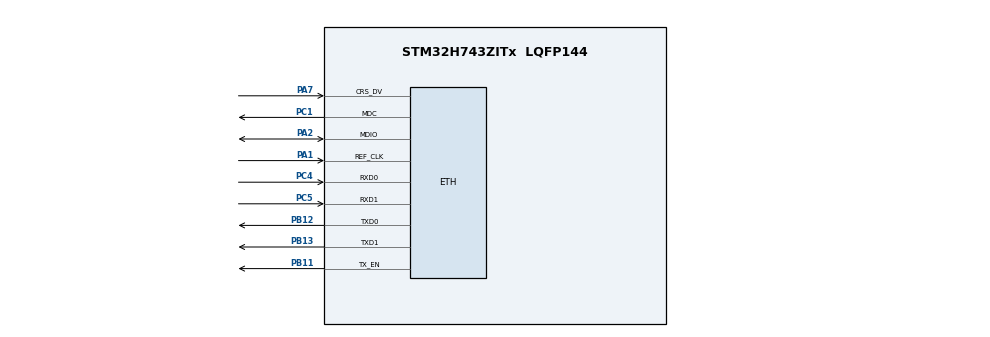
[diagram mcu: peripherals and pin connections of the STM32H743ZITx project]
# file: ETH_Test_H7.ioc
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CORTEX_M7.AccessPermission-Cortex_Memory_Protection_Unit_Region0_Settings=MPU_REGION_FULL_ACCESS
CORTEX_M7.AccessPermission-Cortex_Memory_Protection_Unit_Region1_Settings=MPU_REGION_FULL_ACCESS
CORTEX_M7.BaseAddress-Cortex_Memory_Protection_Unit_Region0_Settings=( uint32_t )&__ETH_BUFFERS_START
CORTEX_M7.BaseAddress-Cortex_Memory_Protection_Unit_Region1_Settings=( uint32_t )&__ETH_DESCRIPTORS_START
CORTEX_M7.CPU_DCache=Enabled
CORTEX_M7.CPU_ICache=Enabled
CORTEX_M7.DisableExec-Cortex_Memory_Protection_Unit_Region0_Settings=MPU_INSTRUCTION_ACCESS_DISABLE
CORTEX_M7.DisableExec-Cortex_Memory_Protection_Unit_Region1_Settings=MPU_INSTRUCTION_ACCESS_DISABLE
CORTEX_M7.Enable-Cortex_Memory_Protection_Unit_Region0_Settings=MPU_REGION_ENABLE
CORTEX_M7.Enable-Cortex_Memory_Protection_Unit_Region1_Settings=MPU_REGION_ENABLE
CORTEX_M7.IsBufferable-Cortex_Memory_Protection_Unit_Region1_Settings=MPU_ACCESS_BUFFERABLE
CORTEX_M7.MPU_Control=MPU_PRIVILEGED_DEFAULT
CORTEX_M7.Size-Cortex_Memory_Protection_Unit_Region0_Settings=MPU_REGION_SIZE_128KB
CORTEX_M7.Size-Cortex_Memory_Protection_Unit_Region1_Settings=MPU_REGION_SIZE_1KB
CORTEX_M7.TypeExtField-Cortex_Memory_Protection_Unit_Region0_Settings=MPU_TEX_LEVEL1
ETH.MediaInterface=HAL_ETH_RMII_MODE
Mcu.Family=STM32H7
Mcu.Name=STM32H743ZITx
Mcu.Package=LQFP144
NVIC.ETH_IRQn=true\:5\:0\:true\:false\:false\:true\:true\:true
NVIC.PriorityGroup=NVIC_PRIORITYGROUP_4
NVIC.TIM6_DAC_IRQn=true\:15\:0\:false\:false\:true\:false\:true\:true
NVIC.TimeBase=TIM6_DAC_IRQn
NVIC.TimeBaseIP=TIM6
PA1.Mode=RMII
PA1.Signal=ETH_REF_CLK
PA2.GPIO_Speed=GPIO_SPEED_FREQ_HIGH
PA2.Mode=RMII
PA2.Signal=ETH_MDIO
PA7.Mode=RMII
PA7.Signal=ETH_CRS_DV
PB11.GPIO_Speed=GPIO_SPEED_FREQ_VERY_HIGH
PB11.Mode=RMII
PB11.Signal=ETH_TX_EN
PB12.GPIO_Speed=GPIO_SPEED_FREQ_VERY_HIGH
PB12.Mode=RMII
PB12.Signal=ETH_TXD0
PB13.GPIO_Speed=GPIO_SPEED_FREQ_VERY_HIGH
PB13.Mode=RMII
PB13.Signal=ETH_TXD1
PC1.GPIO_Speed=GPIO_SPEED_FREQ_HIGH
PC1.Mode=RMII
PC1.Signal=ETH_MDC
PC4.GPIO_Speed=GPIO_SPEED_FREQ_VERY_HIGH
PC4.Mode=RMII
PC4.Signal=ETH_RXD0
PC5.GPIO_Speed=GPIO_SPEED_FREQ_VERY_HIGH
PC5.Mode=RMII
PC5.Signal=ETH_RXD1
PH0-OSC_IN\ (PH0).Mode=HSE-External-Clock-Source
PH0-OSC_IN\ (PH0).Signal=RCC_OSC_IN
ProjectManager.HeapSize=0x400
ProjectManager.StackSize=0x800
ProjectManager.TargetToolchain=STM32CubeIDE
RCC.ADCFreq_Value=16125000
RCC.APB1Freq_Value=120000000
RCC.APB2Freq_Value=120000000
RCC.APB3Freq_Value=120000000
RCC.APB4Freq_Value=120000000
RCC.CortexFreq_Value=480000000
RCC.D1PPRE=RCC_APB3_DIV2
RCC.D2PPRE1=RCC_APB1_DIV2
RCC.D2PPRE2=RCC_APB2_DIV2
RCC.D3PPRE=RCC_APB4_DIV2
RCC.DIVM1=1
RCC.DIVN1=120
RCC.HCLKFreq_Value=240000000
RCC.HPRE=RCC_HCLK_DIV2
RCC.HSE_VALUE=8000000
RCC.PLLFRACN=0
RCC.PLLSourceVirtual=RCC_PLLSOURCE_HSE
RCC.SYSCLKFreq_VALUE=480000000
RCC.SYSCLKSource=RCC_SYSCLKSOURCE_PLLCLK
RCC.USBFreq_Value=480000000
VP_SYS_VS_tim6.Mode=TIM6
board=NUCLEO-H743ZI2

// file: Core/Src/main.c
/* USER CODE BEGIN Header */
/**
  ******************************************************************************
  * @file           : main.c
  * @brief          : Main program body
  ******************************************************************************
  * @attention
  *
  * Copyright (c) 2024 STMicroelectronics.
  * All rights reserved.
  *
  * This software is licensed under terms that can be found in the LICENSE file
  * in the root directory of this software component.
  * If no LICENSE file comes with this software, it is provided AS-IS.
  *
  ******************************************************************************
  */
/* USER CODE END Header */
#include "main.h"
#include "gpio.h"

/* USER CODE BEGIN Includes */
#include <FreeRTOS.h>
#include <task.h>
/* USER CODE END Includes */

void SystemClock_Config(void);
static void MPU_Config(void);

/* USER CODE BEGIN 0 */
extern void CommsTask_vInit();
/* USER CODE END 0 */

int main(void)
{

  /* MPU Configuration--------------------------------------------------------*/
  MPU_Config();
/* Enable the CPU Cache */

  /* Enable I-Cache---------------------------------------------------------*/
  SCB_EnableICache();

  /* Enable D-Cache---------------------------------------------------------*/
  SCB_EnableDCache();

  /* MCU Configuration--------------------------------------------------------*/

  /* Reset of all peripherals, Initializes the Flash interface and the Systick. */
  HAL_Init();

  /* Configure the system clock */
  SystemClock_Config();

  /* Initialize all configured peripherals */
  MX_GPIO_Init();
  /* USER CODE BEGIN 2 */
  CommsTask_vInit();
  vTaskStartScheduler();
  /* USER CODE END 2 */

  /* Infinite loop */
  while (1)
  {

  }
}

void SystemClock_Config(void)
{
  RCC_OscInitTypeDef RCC_OscInitStruct = {0};
  RCC_ClkInitTypeDef RCC_ClkInitStruct = {0};

  /** Supply configuration update enable
  */
  HAL_PWREx_ConfigSupply(PWR_LDO_SUPPLY);

  /** Configure the main internal regulator output voltage
  */
  __HAL_PWR_VOLTAGESCALING_CONFIG(PWR_REGULATOR_VOLTAGE_SCALE1);

  while(!__HAL_PWR_GET_FLAG(PWR_FLAG_VOSRDY)) {}

  __HAL_RCC_SYSCFG_CLK_ENABLE();
  __HAL_PWR_VOLTAGESCALING_CONFIG(PWR_REGULATOR_VOLTAGE_SCALE0);

  while(!__HAL_PWR_GET_FLAG(PWR_FLAG_VOSRDY)) {}

  /** Initializes the RCC Oscillators according to the specified parameters
  * in the RCC_OscInitTypeDef structure.
  */
  RCC_OscInitStruct.OscillatorType = RCC_OSCILLATORTYPE_HSE;
  RCC_OscInitStruct.HSEState = RCC_HSE_BYPASS;
  RCC_OscInitStruct.PLL.PLLState = RCC_PLL_ON;
  RCC_OscInitStruct.PLL.PLLSource = RCC_PLLSOURCE_HSE;
  RCC_OscInitStruct.PLL.PLLM = 1;
  RCC_OscInitStruct.PLL.PLLN = 120;
  RCC_OscInitStruct.PLL.PLLP = 2;
  RCC_OscInitStruct.PLL.PLLQ = 2;
  RCC_OscInitStruct.PLL.PLLR = 2;
  RCC_OscInitStruct.PLL.PLLRGE = RCC_PLL1VCIRANGE_3;
  RCC_OscInitStruct.PLL.PLLVCOSEL = RCC_PLL1VCOWIDE;
  RCC_OscInitStruct.PLL.PLLFRACN = 0;
  if (HAL_RCC_OscConfig(&RCC_OscInitStruct) != HAL_OK)
  {
    Error_Handler();
  }

  /** Initializes the CPU, AHB and APB buses clocks
  */
  RCC_ClkInitStruct.ClockType = RCC_CLOCKTYPE_HCLK|RCC_CLOCKTYPE_SYSCLK
                              |RCC_CLOCKTYPE_PCLK1|RCC_CLOCKTYPE_PCLK2
                              |RCC_CLOCKTYPE_D3PCLK1|RCC_CLOCKTYPE_D1PCLK1;
  RCC_ClkInitStruct.SYSCLKSource = RCC_SYSCLKSOURCE_PLLCLK;
  RCC_ClkInitStruct.SYSCLKDivider = RCC_SYSCLK_DIV1;
  RCC_ClkInitStruct.AHBCLKDivider = RCC_HCLK_DIV2;
  RCC_ClkInitStruct.APB3CLKDivider = RCC_APB3_DIV2;
  RCC_ClkInitStruct.APB1CLKDivider = RCC_APB1_DIV2;
  RCC_ClkInitStruct.APB2CLKDivider = RCC_APB2_DIV2;
  RCC_ClkInitStruct.APB4CLKDivider = RCC_APB4_DIV2;

  if (HAL_RCC_ClockConfig(&RCC_ClkInitStruct, FLASH_LATENCY_4) != HAL_OK)
  {
    Error_Handler();
  }
}

/* MPU Configuration */

void MPU_Config(void)
{
  MPU_Region_InitTypeDef MPU_InitStruct = {0};

  HAL_MPU_Disable();

  // Default
  MPU_InitStruct.Enable = MPU_REGION_ENABLE;
  MPU_InitStruct.Number = MPU_REGION_NUMBER0;
    MPU_InitStruct.BaseAddress = 0x00;
    MPU_InitStruct.Size = MPU_REGION_SIZE_4GB;
    MPU_InitStruct.SubRegionDisable = 0x87;
    MPU_InitStruct.TypeExtField = MPU_TEX_LEVEL0;
    MPU_InitStruct.AccessPermission = MPU_REGION_NO_ACCESS;
    MPU_InitStruct.DisableExec = MPU_INSTRUCTION_ACCESS_DISABLE;
    MPU_InitStruct.IsBufferable = MPU_ACCESS_NOT_BUFFERABLE;
    MPU_InitStruct.IsCacheable = MPU_ACCESS_NOT_CACHEABLE;
    MPU_InitStruct.IsShareable = MPU_ACCESS_SHAREABLE;
    HAL_MPU_ConfigRegion(&MPU_InitStruct);

  // DTCM RAM
     MPU_InitStruct.Enable = MPU_REGION_ENABLE;
     MPU_InitStruct.Number = MPU_REGION_NUMBER1;
     MPU_InitStruct.BaseAddress = 0x20000000;
     MPU_InitStruct.Size = MPU_REGION_SIZE_128KB;
     MPU_InitStruct.SubRegionDisable = 0;
     MPU_InitStruct.TypeExtField = MPU_TEX_LEVEL0;
     MPU_InitStruct.AccessPermission = MPU_REGION_FULL_ACCESS;
     MPU_InitStruct.DisableExec = MPU_INSTRUCTION_ACCESS_ENABLE;
     MPU_InitStruct.IsShareable = MPU_ACCESS_SHAREABLE;
     MPU_InitStruct.IsCacheable = MPU_ACCESS_CACHEABLE;
     MPU_InitStruct.IsBufferable = MPU_ACCESS_NOT_BUFFERABLE;
     HAL_MPU_ConfigRegion(&MPU_InitStruct);

     // AXI SRAM
	MPU_InitStruct.Enable = MPU_REGION_ENABLE;
	MPU_InitStruct.Number = MPU_REGION_NUMBER2;
	MPU_InitStruct.BaseAddress = 0x24000000;
	MPU_InitStruct.Size = MPU_REGION_SIZE_512KB;
	MPU_InitStruct.SubRegionDisable = 0;
	MPU_InitStruct.TypeExtField = MPU_TEX_LEVEL0;
	MPU_InitStruct.AccessPermission = MPU_REGION_FULL_ACCESS;
	MPU_InitStruct.DisableExec = MPU_INSTRUCTION_ACCESS_ENABLE;
	MPU_InitStruct.IsShareable = MPU_ACCESS_SHAREABLE;
	MPU_InitStruct.IsCacheable = MPU_ACCESS_CACHEABLE;
	MPU_InitStruct.IsBufferable = MPU_ACCESS_NOT_BUFFERABLE;
	HAL_MPU_ConfigRegion(&MPU_InitStruct);

	// AHB SRAM
	   MPU_InitStruct.Enable = MPU_REGION_ENABLE;
	   MPU_InitStruct.Number = MPU_REGION_NUMBER3;
	   MPU_InitStruct.BaseAddress = 0x30000000;
	   MPU_InitStruct.Size = MPU_REGION_SIZE_256KB;
	   MPU_InitStruct.SubRegionDisable = 0;
	   MPU_InitStruct.TypeExtField = MPU_TEX_LEVEL0;
	   MPU_InitStruct.AccessPermission = MPU_REGION_FULL_ACCESS;
	   MPU_InitStruct.DisableExec = MPU_INSTRUCTION_ACCESS_ENABLE;
	   MPU_InitStruct.IsShareable = MPU_ACCESS_SHAREABLE;
	   MPU_InitStruct.IsCacheable = MPU_ACCESS_CACHEABLE;
	   MPU_InitStruct.IsBufferable = MPU_ACCESS_BUFFERABLE;
	   HAL_MPU_ConfigRegion(&MPU_InitStruct);

	   // AHB SRAM (no cache)
	   MPU_InitStruct.Enable = MPU_REGION_ENABLE;
	   MPU_InitStruct.Number = MPU_REGION_NUMBER4;
	   MPU_InitStruct.BaseAddress = 0x30040000;
	   MPU_InitStruct.Size = MPU_REGION_SIZE_32KB;
	   MPU_InitStruct.SubRegionDisable = 0;
	   MPU_InitStruct.TypeExtField = MPU_TEX_LEVEL0;
	   MPU_InitStruct.AccessPermission = MPU_REGION_FULL_ACCESS;
	   MPU_InitStruct.DisableExec = MPU_INSTRUCTION_ACCESS_ENABLE;
	   MPU_InitStruct.IsShareable = MPU_ACCESS_SHAREABLE;
	   MPU_InitStruct.IsCacheable = MPU_ACCESS_NOT_CACHEABLE;
	   MPU_InitStruct.IsBufferable = MPU_ACCESS_NOT_BUFFERABLE;
	   HAL_MPU_ConfigRegion(&MPU_InitStruct);

   //Eth Buffers
   extern uint8_t __ETH_BUFFERS_START;
  MPU_InitStruct.Enable = MPU_REGION_ENABLE;
  MPU_InitStruct.Number = MPU_REGION_NUMBER5;
  MPU_InitStruct.BaseAddress = ( uint32_t )&__ETH_BUFFERS_START;
  MPU_InitStruct.Size = MPU_REGION_SIZE_128KB;
  MPU_InitStruct.SubRegionDisable = 0x0;
  MPU_InitStruct.TypeExtField = MPU_TEX_LEVEL1;
  MPU_InitStruct.AccessPermission = MPU_REGION_FULL_ACCESS;
  MPU_InitStruct.DisableExec = MPU_INSTRUCTION_ACCESS_DISABLE;
  MPU_InitStruct.IsShareable = MPU_ACCESS_NOT_SHAREABLE;
  MPU_InitStruct.IsCacheable = MPU_ACCESS_NOT_CACHEABLE;
  MPU_InitStruct.IsBufferable = MPU_ACCESS_NOT_BUFFERABLE;
  HAL_MPU_ConfigRegion(&MPU_InitStruct);

  // Eth Descriptors
  extern uint8_t __ETH_DESCRIPTORS_START;
  MPU_InitStruct.Enable = MPU_REGION_ENABLE;
  MPU_InitStruct.Number = MPU_REGION_NUMBER6;
  MPU_InitStruct.BaseAddress = ( uint32_t )&__ETH_DESCRIPTORS_START;
  MPU_InitStruct.Size = MPU_REGION_SIZE_1KB;
  MPU_InitStruct.SubRegionDisable = 0x0;
  MPU_InitStruct.TypeExtField = MPU_TEX_LEVEL0;
  MPU_InitStruct.AccessPermission = MPU_REGION_FULL_ACCESS;
  MPU_InitStruct.DisableExec = MPU_INSTRUCTION_ACCESS_DISABLE;
  MPU_InitStruct.IsShareable = MPU_ACCESS_NOT_SHAREABLE;
  MPU_InitStruct.IsCacheable = MPU_ACCESS_NOT_CACHEABLE;
  MPU_InitStruct.IsBufferable = MPU_ACCESS_BUFFERABLE;
  HAL_MPU_ConfigRegion(&MPU_InitStruct);

  HAL_MPU_Enable(MPU_PRIVILEGED_DEFAULT);
}

void HAL_TIM_PeriodElapsedCallback(TIM_HandleTypeDef *htim)
{
  if (htim->Instance == TIM6) {
    HAL_IncTick();
  }
}

void Error_Handler(void)
{
  __disable_irq();
  while (1)
  {
  }
}
